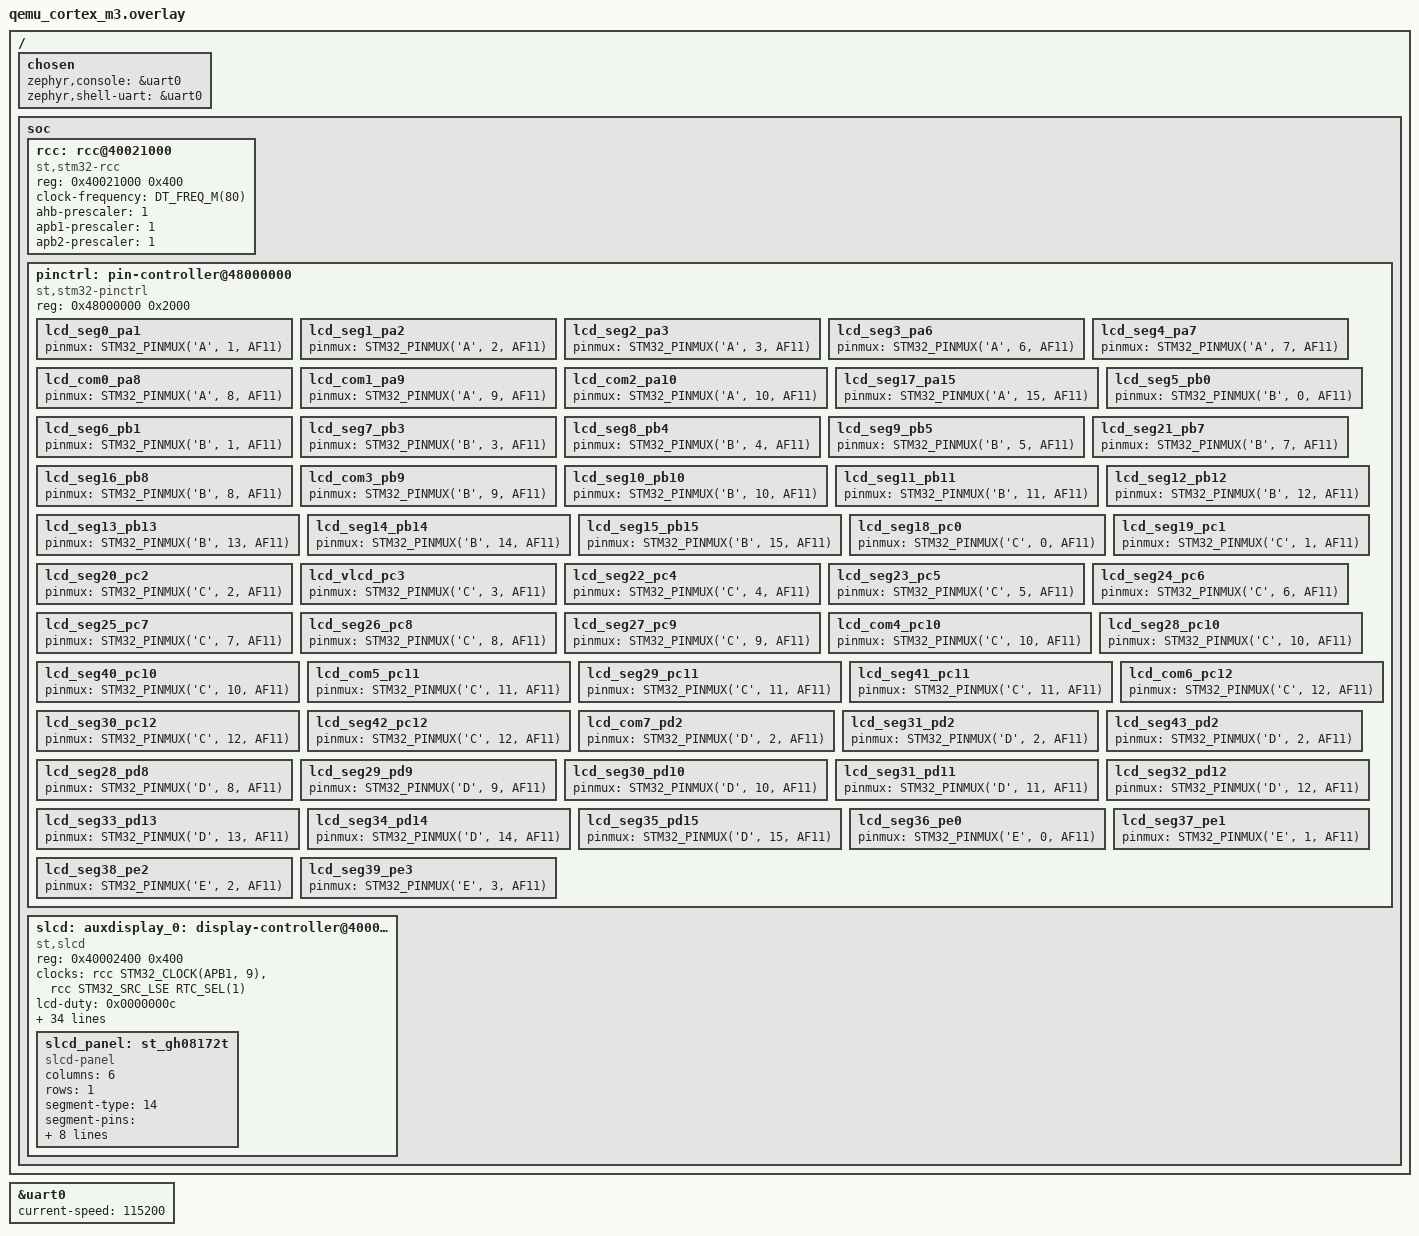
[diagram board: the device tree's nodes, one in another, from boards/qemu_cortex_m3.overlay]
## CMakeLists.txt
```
# SPDX-License-Identifier: Apache-2.0

message(STATUS "Start of CMakeList.txt")

cmake_minimum_required(VERSION 3.20.0)

message(STATUS "CMake current source dir is: ${CMAKE_CURRENT_SOURCE_DIR}")
list(APPEND DTS_ROOT "${CMAKE_CURRENT_SOURCE_DIR}")

find_package(Zephyr REQUIRED HINTS $ENV{ZEPHYR_BASE})

message(STATUS "Zephyr base is: ${ZEPHYR_BASE}")
list(APPEND DTS_ROOT "${ZEPHYR_BASE}/drivers/auxdisplay")

project(auxdisplay_14seg_qemu)

include_directories(SYSTEM src)
target_compile_options(app PRIVATE "-include" "${CMAKE_CURRENT_SOURCE_DIR}/src/mock_stm32l4xx_hal.h")
if(TARGET zephyr_interface)
	target_compile_options(zephyr_interface INTERFACE "-include" "${CMAKE_CURRENT_SOURCE_DIR}/src/mock_stm32l4xx_hal.h")
endif()

target_sources(app PRIVATE
	src/main.c
	src/mock_pinctrl_soc.c
	src/mock_stm32_clock_control.c
	src/mock_stm32l4xx_hal.c)

# Driver files to test
zephyr_library_include_directories("${CMAKE_CURRENT_SOURCE_DIR}/src")
zephyr_library_sources(
	"${ZEPHYR_BASE}/drivers/auxdisplay/auxdisplay_slcd_14seg.c"
	"${ZEPHYR_BASE}/drivers/auxdisplay/auxdisplay_st_slcd.c")

message(STATUS "End of CMakeList.txt")
```

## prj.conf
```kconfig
CONFIG_LOG=y
CONFIG_AUXDISPLAY=y

CONFIG_AUXDISPLAY_ST_SLCD=n

CONFIG_UART_CONSOLE=y

CONFIG_ZTEST=y
CONFIG_ZTEST_ASSERT_VERBOSE=3

# Added automatically by Workbench for Zephyr
#--- DEBUG PRESET - BEGIN ---#
# Set to -Og
CONFIG_DEBUG_OPTIMIZATIONS=y
# Thread awareness support
CONFIG_DEBUG_THREAD_INFO=y
# Generate stack usage per-function
CONFIG_STACK_USAGE=y
# Other options in case not set by default
CONFIG_BUILD_OUTPUT_HEX=y
CONFIG_BUILD_OUTPUT_META=y
CONFIG_OUTPUT_SYMBOLS=y
CONFIG_OUTPUT_STAT=y
CONFIG_OUTPUT_DISASSEMBLY=y
CONFIG_OUTPUT_PRINT_MEMORY_USAGE=y
#--- DEBUG PRESET - END ---#
```

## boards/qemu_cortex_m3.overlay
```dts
#include <zephyr/dt-bindings/clock/stm32l4_clock.h>
#include <freq.h>

/ {
	chosen {
		zephyr,console = &uart0;
		zephyr,shell-uart = &uart0;
	};

	soc {
		rcc: rcc@40021000 {
			compatible = "st,stm32-rcc";
			#clock-cells = <2>;
			reg = <0x40021000 0x400>;
		};

		pinctrl: pin-controller@48000000 {
			compatible = "st,stm32-pinctrl";
			reg = <0x48000000 0x2000>;
			#address-cells = <1>;
			#size-cells = <1>;
			reg = <0x48000000 0x2000>;
			ranges;
		};

		slcd: display-controller@40002400 {
			compatible = "st,slcd";
			reg = <0x40002400 0x400>;
			clocks = <&rcc STM32_CLOCK(APB1, 9)>, <&rcc STM32_SRC_LSE RTC_SEL(1)>;
			clock-names = "bus", "device";
		};
	};
};

&uart0 {
    status = "okay";
    current-speed = <115200>;
};

&rcc {
	//clocks = <&pll>;
	clock-frequency = <DT_FREQ_M(80)>;
	ahb-prescaler = <1>;
	apb1-prescaler = <1>;
	apb2-prescaler = <1>;
};

&slcd {
	status = "okay";
	lcd-duty = <0x0000000c>;
	lcd-bias = <0x00000040>;
	lcd-mux-segment = <0>;
	lcd-voltage-source = <0>;
	lcd-prescaler = <0>;
	lcd-divider = <0x003c0000>;
	lcd-contrast = <0x00001400>;
	lcd-pulse-on-duration = <0x00000040>;
	lcd-dead-time = <0>;
	lcd-high-drive = <0>;
	lcd-blink-mode = <0>;
	lcd-blink-frequency = <0x00004000>;
	pinctrl-0 = <&lcd_seg3_pa6 &lcd_seg4_pa7 &lcd_com0_pa8
		     &lcd_com1_pa9 &lcd_com2_pa10 &lcd_seg17_pa15
		     &lcd_seg5_pb0 &lcd_seg6_pb1 &lcd_seg8_pb4
		     &lcd_seg9_pb5 &lcd_com3_pb9 &lcd_seg12_pb12
		     &lcd_seg13_pb13 &lcd_seg14_pb14 &lcd_seg15_pb15
		     &lcd_vlcd_pc3 &lcd_seg22_pc4 &lcd_seg23_pc5
		     &lcd_seg24_pc6 &lcd_seg25_pc7 &lcd_seg26_pc8
		     &lcd_seg28_pd8 &lcd_seg29_pd9 &lcd_seg30_pd10 &lcd_seg31_pd11
		     &lcd_seg32_pd12 &lcd_seg33_pd13 &lcd_seg34_pd14 &lcd_seg35_pd15>;
	pinctrl-names = "default";
	pin-list = <4 23 6 13 15 29 31 33 35 25 17 8 9 26 24 34 32 30 28 14 12 5 22 3>;
	com-list = <0 2 4 6 1 3 5 7>;
	character-bit-list = <
			      /* MCU AFP11 channel for segment 1A-1P */
			      (1 << 22) (1 << 22) (1 << 23) (1 << 4) (1 << 4) (1 << 3) (1 << 3)
			      (1 << 3) (1 << 22) (1 << 22) (1 << 23) (1 << 4) (1 << 4) (1 << 3)
			      /* MCU AFP11 channel for segment 2A-2P */
			      (1 << 12) (1 << 12) (1 << 13) (1 << 6) (1 << 6) (1 << 5) (1 << 5)
			      (1 << 5) (1 << 12) (1 << 12) (1 << 13) (1 << 6) (1 << 6) (1 << 5)
			      /* MCU AFP11 channel for segment 1A-1P */
			      (1 << 28) (1 << 28) (1 << 29) (1 << 15) (1 << 15) (1 << 14) (1 << 14)
			      (1 << 14) (1 << 28) (1 << 28) (1 << 29) (1 << 15) (1 << 15) (1 << 14)
			      /* MCU AFP11 channel for segment 2A-2P */
			      (1 << 0) (1 << 0) (1 << 1) (1 << 31) (1 << 31) (1 << 30) (1 << 30)
			      (1 << 30) (1 << 0) (1 << 0) (1 << 1) (1 << 31) (1 << 31) (1 << 30)
			      /* MCU AFP11 channel for segment 3A-3P */
			      (1 << 24) (1 << 24) (1 << 25) (1 << 3) (1 << 3) (1 << 2) (1 << 2)
			      (1 << 2)
			      (1 << 24) (1 << 24) (1 << 25) (1 << 3) (1 << 3) (1 << 2)
			      /* MCU AFP11 channel for segment 4A-4P */
			      (1 << 9) (1 << 9) (1 << 8) (1 << 17) (1 << 17) (1 << 26) (1 << 26)
			      (1 << 26)
			      (1 << 9) (1 << 9) (1 << 8) (1 << 17) (1 << 17) (1 << 26)>;
	character-com-list = <
			      /* COM RAM register for segment 1A-1P */
			      2 0 2 2 0 2 0 6 6 4 0 6 4 4
			      /* COM RAM register for segment 2A-2P */
			      2 0 2 2 0 2 0 6 6 4 0 6 4 4
			      /* COM RAM register for segment 1A-1P */
			      2 0 2 2 0 2 0 6 6 4 0 6 4 4
			      /* COM RAM register for segment 2A-2P */
			      3 1 3 2 0 2 0 6 7 5 1 6 4 4
			      /* COM RAM register for segment 3A-3P */
			      2 0 2 3 1 3 1 7 6 4 0 7 5 5
			      /* COM RAM register for segment 4A-4P */
			      2 0 2 2 0 2 0 6 6 4 0 6 4 4>;
	indicator-bit-list = <(1 << 23) (1 << 23) (1 << 13) (1 << 13)
			      (1 << 29) (1 << 29) (1 << 1) (1 << 1)
			      (1 << 8) (1 << 8) (1 << 25) (1 << 25)>;
	indicator-com-list = <6 4 6 4 6 4 7 5 6 4 6 4>;
	custom-character-slot-count = <32>;
};

auxdisplay_0: &slcd {
	slcd_panel: st_gh08172t {
		compatible = "slcd-panel";
		columns = <6>;
		rows = <1>;
		segment-type = <14>; /* 14 segment SLCD panel */
		/* Which pin controls which segment. 6 positions x 14 segments = 84 elements.
		 * Segment order per position: A B C D E F G H J K M N O P
		 * Since the display starts from left to right
		 */
		segment-pins = <
				/* Pins for dig1 segments(1A~1P) */
				22 22 1 0 0 23 23 23 22 22 1 0 0 23
				/* Pins for dig2 segments(2A~2P) */
				20 20 3 2 2 21 21 21 20 20 3 2 2 21
				/* Pins for dig3 segments(3A~3P) */
				18 18 5 4 4 19 19 19 18 18 5 4 4 19
				/* Pins for dig4 segments(4A~4P) */
				16 16 7 6 6 17 17 17 16 16 7 6 6 17
				/* Pins for dig5 segments(5A~5P) */
				14 14 9 8 8 15 15 15 14 14 9 8 8 15
				/* Pins for dig6 segments(6A~6P) */
				12 12 11 10 10 13 13 13 12 12 11 10 10 13>;

		/* Which com controls which segment. 6 positions x 14 segments = 84 elements. */
		segment-coms = <
				/* COMs for dig1 segments(1A~1P) */
				1 0 1 1 0 1 0 3 3 2 0 3 2 2
				/* COMs for dig2 segments(2A~2P) */
				1 0 1 1 0 1 0 3 3 2 0 3 2 2
				/* COMs for dig3 segments(3A~3P) */
				1 0 1 1 0 1 0 3 3 2 0 3 2 2
				/* COMs for dig4 segments(4A~4P) */
				1 0 1 1 0 1 0 3 3 2 0 3 2 2
				/* COMs for dig5 segments(5A~5P) */
				1 0 1 1 0 1 0 3 3 2 0 3 2 2
				/* COMs for dig6 segments(6A~6P) */
				1 0 1 1 0 1 0 3 3 2 0 3 2 2>;

		num-indicators = <12>;
		indicator-pins = <1 1 3 3 5 5 7 7 11 11 9 9>;
		indicator-coms = <3 2 3 2 3 2 3 2 3 2 3 2>;
		display-indicators = <
				      /* Single dot */
				      0 2 4 6 0xff 0xff
				      /* Double dot (colon) */
				      1 3 5 7 0xff 0xff
				      /* 4 bars, BAR0-BAR3 */
				      0xff 0xff 0xff 0xff 0xff 8
				      0xff 0xff 0xff 0xff 0xff 9
				      0xff 0xff 0xff 0xff 0xff 10
				      0xff 0xff 0xff 0xff 0xff 11>;
	};
};

#include <zephyr/dt-bindings/pinctrl/stm32-pinctrl.h>

&pinctrl {
	/* LCD */

	/omit-if-no-ref/ lcd_seg0_pa1: lcd_seg0_pa1 {
		pinmux = <STM32_PINMUX('A', 1, AF11)>;
	};

	/omit-if-no-ref/ lcd_seg1_pa2: lcd_seg1_pa2 {
		pinmux = <STM32_PINMUX('A', 2, AF11)>;
	};

	/omit-if-no-ref/ lcd_seg2_pa3: lcd_seg2_pa3 {
		pinmux = <STM32_PINMUX('A', 3, AF11)>;
	};

	/omit-if-no-ref/ lcd_seg3_pa6: lcd_seg3_pa6 {
		pinmux = <STM32_PINMUX('A', 6, AF11)>;
	};

	/omit-if-no-ref/ lcd_seg4_pa7: lcd_seg4_pa7 {
		pinmux = <STM32_PINMUX('A', 7, AF11)>;
	};

	/omit-if-no-ref/ lcd_com0_pa8: lcd_com0_pa8 {
		pinmux = <STM32_PINMUX('A', 8, AF11)>;
	};

	/omit-if-no-ref/ lcd_com1_pa9: lcd_com1_pa9 {
		pinmux = <STM32_PINMUX('A', 9, AF11)>;
	};

	/omit-if-no-ref/ lcd_com2_pa10: lcd_com2_pa10 {
		pinmux = <STM32_PINMUX('A', 10, AF11)>;
	};

	/omit-if-no-ref/ lcd_seg17_pa15: lcd_seg17_pa15 {
		pinmux = <STM32_PINMUX('A', 15, AF11)>;
	};

	/omit-if-no-ref/ lcd_seg5_pb0: lcd_seg5_pb0 {
		pinmux = <STM32_PINMUX('B', 0, AF11)>;
	};

	/omit-if-no-ref/ lcd_seg6_pb1: lcd_seg6_pb1 {
		pinmux = <STM32_PINMUX('B', 1, AF11)>;
	};

	/omit-if-no-ref/ lcd_seg7_pb3: lcd_seg7_pb3 {
		pinmux = <STM32_PINMUX('B', 3, AF11)>;
	};

	/omit-if-no-ref/ lcd_seg8_pb4: lcd_seg8_pb4 {
		pinmux = <STM32_PINMUX('B', 4, AF11)>;
	};

	/omit-if-no-ref/ lcd_seg9_pb5: lcd_seg9_pb5 {
		pinmux = <STM32_PINMUX('B', 5, AF11)>;
	};

	/omit-if-no-ref/ lcd_seg21_pb7: lcd_seg21_pb7 {
		pinmux = <STM32_PINMUX('B', 7, AF11)>;
	};

	/omit-if-no-ref/ lcd_seg16_pb8: lcd_seg16_pb8 {
		pinmux = <STM32_PINMUX('B', 8, AF11)>;
	};

	/omit-if-no-ref/ lcd_com3_pb9: lcd_com3_pb9 {
		pinmux = <STM32_PINMUX('B', 9, AF11)>;
	};

	/omit-if-no-ref/ lcd_seg10_pb10: lcd_seg10_pb10 {
		pinmux = <STM32_PINMUX('B', 10, AF11)>;
	};

	/omit-if-no-ref/ lcd_seg11_pb11: lcd_seg11_pb11 {
		pinmux = <STM32_PINMUX('B', 11, AF11)>;
	};

	/omit-if-no-ref/ lcd_seg12_pb12: lcd_seg12_pb12 {
		pinmux = <STM32_PINMUX('B', 12, AF11)>;
	};

	/omit-if-no-ref/ lcd_seg13_pb13: lcd_seg13_pb13 {
		pinmux = <STM32_PINMUX('B', 13, AF11)>;
	};

	/omit-if-no-ref/ lcd_seg14_pb14: lcd_seg14_pb14 {
		pinmux = <STM32_PINMUX('B', 14, AF11)>;
	};

	/omit-if-no-ref/ lcd_seg15_pb15: lcd_seg15_pb15 {
		pinmux = <STM32_PINMUX('B', 15, AF11)>;
	};

	/omit-if-no-ref/ lcd_seg18_pc0: lcd_seg18_pc0 {
		pinmux = <STM32_PINMUX('C', 0, AF11)>;
	};

	/omit-if-no-ref/ lcd_seg19_pc1: lcd_seg19_pc1 {
		pinmux = <STM32_PINMUX('C', 1, AF11)>;
	};

	/omit-if-no-ref/ lcd_seg20_pc2: lcd_seg20_pc2 {
		pinmux = <STM32_PINMUX('C', 2, AF11)>;
	};

	/omit-if-no-ref/ lcd_vlcd_pc3: lcd_vlcd_pc3 {
		pinmux = <STM32_PINMUX('C', 3, AF11)>;
	};

	/omit-if-no-ref/ lcd_seg22_pc4: lcd_seg22_pc4 {
		pinmux = <STM32_PINMUX('C', 4, AF11)>;
	};

	/omit-if-no-ref/ lcd_seg23_pc5: lcd_seg23_pc5 {
		pinmux = <STM32_PINMUX('C', 5, AF11)>;
	};

	/omit-if-no-ref/ lcd_seg24_pc6: lcd_seg24_pc6 {
		pinmux = <STM32_PINMUX('C', 6, AF11)>;
	};

	/omit-if-no-ref/ lcd_seg25_pc7: lcd_seg25_pc7 {
		pinmux = <STM32_PINMUX('C', 7, AF11)>;
	};

	/omit-if-no-ref/ lcd_seg26_pc8: lcd_seg26_pc8 {
		pinmux = <STM32_PINMUX('C', 8, AF11)>;
	};

	/omit-if-no-ref/ lcd_seg27_pc9: lcd_seg27_pc9 {
		pinmux = <STM32_PINMUX('C', 9, AF11)>;
	};

	/omit-if-no-ref/ lcd_com4_pc10: lcd_com4_pc10 {
		pinmux = <STM32_PINMUX('C', 10, AF11)>;
	};

	/omit-if-no-ref/ lcd_seg28_pc10: lcd_seg28_pc10 {
		pinmux = <STM32_PINMUX('C', 10, AF11)>;
	};

	/omit-if-no-ref/ lcd_seg40_pc10: lcd_seg40_pc10 {
		pinmux = <STM32_PINMUX('C', 10, AF11)>;
	};

	/omit-if-no-ref/ lcd_com5_pc11: lcd_com5_pc11 {
		pinmux = <STM32_PINMUX('C', 11, AF11)>;
	};

	/omit-if-no-ref/ lcd_seg29_pc11: lcd_seg29_pc11 {
		pinmux = <STM32_PINMUX('C', 11, AF11)>;
	};

	/omit-if-no-ref/ lcd_seg41_pc11: lcd_seg41_pc11 {
		pinmux = <STM32_PINMUX('C', 11, AF11)>;
	};

	/omit-if-no-ref/ lcd_com6_pc12: lcd_com6_pc12 {
		pinmux = <STM32_PINMUX('C', 12, AF11)>;
	};

	/omit-if-no-ref/ lcd_seg30_pc12: lcd_seg30_pc12 {
		pinmux = <STM32_PINMUX('C', 12, AF11)>;
	};

	/omit-if-no-ref/ lcd_seg42_pc12: lcd_seg42_pc12 {
		pinmux = <STM32_PINMUX('C', 12, AF11)>;
	};

	/omit-if-no-ref/ lcd_com7_pd2: lcd_com7_pd2 {
		pinmux = <STM32_PINMUX('D', 2, AF11)>;
	};

	/omit-if-no-ref/ lcd_seg31_pd2: lcd_seg31_pd2 {
		pinmux = <STM32_PINMUX('D', 2, AF11)>;
	};

	/omit-if-no-ref/ lcd_seg43_pd2: lcd_seg43_pd2 {
		pinmux = <STM32_PINMUX('D', 2, AF11)>;
	};

	/omit-if-no-ref/ lcd_seg28_pd8: lcd_seg28_pd8 {
		pinmux = <STM32_PINMUX('D', 8, AF11)>;
	};

	/omit-if-no-ref/ lcd_seg29_pd9: lcd_seg29_pd9 {
		pinmux = <STM32_PINMUX('D', 9, AF11)>;
	};

	/omit-if-no-ref/ lcd_seg30_pd10: lcd_seg30_pd10 {
		pinmux = <STM32_PINMUX('D', 10, AF11)>;
	};

	/omit-if-no-ref/ lcd_seg31_pd11: lcd_seg31_pd11 {
		pinmux = <STM32_PINMUX('D', 11, AF11)>;
	};

	/omit-if-no-ref/ lcd_seg32_pd12: lcd_seg32_pd12 {
		pinmux = <STM32_PINMUX('D', 12, AF11)>;
	};

	/omit-if-no-ref/ lcd_seg33_pd13: lcd_seg33_pd13 {
		pinmux = <STM32_PINMUX('D', 13, AF11)>;
	};

	/omit-if-no-ref/ lcd_seg34_pd14: lcd_seg34_pd14 {
		pinmux = <STM32_PINMUX('D', 14, AF11)>;
	};

	/omit-if-no-ref/ lcd_seg35_pd15: lcd_seg35_pd15 {
		pinmux = <STM32_PINMUX('D', 15, AF11)>;
	};

	/omit-if-no-ref/ lcd_seg36_pe0: lcd_seg36_pe0 {
		pinmux = <STM32_PINMUX('E', 0, AF11)>;
	};

	/omit-if-no-ref/ lcd_seg37_pe1: lcd_seg37_pe1 {
		pinmux = <STM32_PINMUX('E', 1, AF11)>;
	};

	/omit-if-no-ref/ lcd_seg38_pe2: lcd_seg38_pe2 {
		pinmux = <STM32_PINMUX('E', 2, AF11)>;
	};

	/omit-if-no-ref/ lcd_seg39_pe3: lcd_seg39_pe3 {
		pinmux = <STM32_PINMUX('E', 3, AF11)>;
	};
};
```

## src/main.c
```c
/*
 * Copyright (c) 2026 Renato Mauro
 *
 * SPDX-License-Identifier: Apache-2.0
 */

#include <string.h>
#include <zephyr/kernel.h>
#include <zephyr/device.h>
#include <zephyr/drivers/auxdisplay.h>
#include <zephyr/logging/log.h>
#include <zephyr/ztest.h>

LOG_MODULE_REGISTER(auxdisplay_14seg_qemu, LOG_LEVEL_DBG);

struct auxdisplay_panel_config {
	struct auxdisplay_capabilities capabilities;
	const bool rotated;
	const uint8_t segment_type;
	const uint16_t *digits; /* Digits coding array. */
	const uint16_t *digits_rotated_180;
	const uint16_t *letters_upper; /* Upper Letter coding array. */
	const uint16_t *letters_upper_rotated_180;
	const uint16_t *letters_lower; /* Lower Letter coding array. */
	const uint16_t *letters_lower_rotated_180;
	/*
	 * Pin/com configurations of the segments/indicators read from the
	 * panel overlay configuration.
	 */
	const uint8_t *segment_pins;
	const uint8_t *segment_coms;
	const uint8_t num_indicators;
	const uint8_t *indicator_pins;       /* Optional. NULL if DT property absent */
	const uint8_t *indicator_coms;       /* Optional. NULL if DT property absent */
	const uint8_t *display_indicators;   /* Optional. NULL if DT property absent */
	const uint8_t *col_indicators;       /* Optional. NULL if DT property absent */
	const uint8_t *upper_dot_indicators; /* Optional. NULL if DT property absent */
	const uint8_t *lower_dot_indicators; /* Optional. NULL if DT property absent */
};

struct auxdisplay_st_slcd_config {
	const struct stm32_pclken *pclken;
	const struct device *clk_dev;
	const struct pinctrl_dev_config *pincfg;

	const uint8_t *pin_list;
	const uint8_t pin_list_len;
	const uint8_t com_list_len;
	const uint8_t ram_buffer_size;

	const uint8_t custom_character_slot_count;
	const uint32_t *character_bit_list;
	const uint8_t *character_com_list;
	const uint32_t *indicator_bit_list;
	const uint8_t *indicator_com_list;

	const struct auxdisplay_panel_config *panel_config;
	const int position_count;
};

extern uint16_t
slcd_14seg_convert_ascii_char_to_14seg_pattern(const struct auxdisplay_panel_config *panel,
					       uint8_t ascii_char);

struct full_test_fixture {
	const struct device *display;
	const struct auxdisplay_panel_config *panel_config;
};

static void *suite_setup(void)
{
	static struct full_test_fixture context;

	context.display = DEVICE_DT_GET(DT_NODELABEL(auxdisplay_0));
	context.panel_config = ((const struct auxdisplay_st_slcd_config *)context.display->config)->panel_config;
	return &context;
}

ZTEST_SUITE(full_test, NULL, suite_setup, NULL, NULL, NULL);

ZTEST_F(full_test, test_display_ready)
{
	zassert_not_null(fixture->display, "Segment LCD device not instantiated");
	zassert_true(device_is_ready(fixture->display),
		     "Segment LCD device is not ready for operation");
	zassert_not_null(fixture->panel_config, "Segment LCD panel config not found");
}

ZTEST_F(full_test, test_auxdisplay_write_uppercase_a)
{
	const char t = 'A';
	int rc = auxdisplay_write(fixture->display, (const uint8_t *)&t, 1);
	zassert_equal(rc, 0, "La scrittura su auxdisplay ha fallito (%d)", rc);
}

ZTEST_F(full_test, test_auxdisplay_write_uppercase_z)
{
	const char t = 'Z';
	int rc = auxdisplay_write(fixture->display, (const uint8_t *)&t, 1);

	zassert_equal(rc, 0, "La scrittura su auxdisplay ha fallito (%d)", rc);
}

ZTEST_F(full_test, test_slcd_14seg_convert_ascii_char_to_14seg_pattern_uppercase_a)
{
	uint16_t pattern = slcd_14seg_convert_ascii_char_to_14seg_pattern(fixture->panel_config, 'A');

	zassert_equal(pattern, 0x477, "Pattern for letter 'A' is wrong (0x%x)", pattern);
}

ZTEST_F(full_test, test_slcd_14seg_convert_ascii_char_to_14seg_pattern_uppercase_z)
{
	uint16_t pattern = slcd_14seg_convert_ascii_char_to_14seg_pattern(fixture->panel_config, 'Z');

	zassert_equal(pattern, 0x2209, "Pattern for letter 'A' is wrong (0x%x)", pattern);
}
```

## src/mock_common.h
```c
/*
 * Copyright 2026 Renato Mauro
 *
 * SPDX-License-Identifier: Apache-2.0
 */

#ifndef MOCK_COMMON_H
#define MOCK_COMMON_H

#include <stdint.h>

#ifdef __used
#undef __used
#endif

/* Define mock identifiers and types to make the code compile */
#if !defined(UNUSED)
#define UNUSED(x) ((void)(x))
#endif

#endif /* MOCK_COMMON_H */
```

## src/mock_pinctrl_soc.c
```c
/*
 * Copyright (c) 2026 Renato Mauro
 *
 * SPDX-License-Identifier: Apache-2.0
 */

#include <string.h>
#include <zephyr/kernel.h>
#include <zephyr/device.h>

#include "mock_common.h"
/** pinctrl_soc.h is included via pinctrl.h, that exists also in the QEMU environment.
 * For this reason, it must be mocked with a file having the same name.
 */
#include "pinctrl_soc.h"

struct pinctrl_dev_config;

int pinctrl_lookup_state(const struct pinctrl_dev_config *config, uint8_t state, uint8_t *idx)
{
	UNUSED(config);
	UNUSED(state);
	if (idx) {
		*idx = 0;
	}
	return 0;
}

int pinctrl_configure_pins(const pinctrl_soc_pin_t *pins, uint8_t pin_cnt, uintptr_t reg)
{
	UNUSED(pins);
	UNUSED(pin_cnt);
	UNUSED(reg);
	return 0;
}
```

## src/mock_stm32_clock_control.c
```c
/*
 * Copyright (c) 2026 Renato Mauro
 *
 * SPDX-License-Identifier: Apache-2.0
 */

#include <string.h>
#include <zephyr/kernel.h>
#include <zephyr/device.h>

#include <zephyr/toolchain.h>
#include <zephyr/drivers/clock_control.h>

#include "mock_common.h"
#include "mock_stm32_clock_control.h"

static struct device_state mock_device_state = {
	.init_res = 0, /* 0 in Zephyr means successfully initialized */
	.initialized = true,
};

static int mock_clock_on(const struct device *dev, clock_control_subsys_t sys)
{
	UNUSED(dev);
	UNUSED(sys);
	return 0; /* Ritorna successo */
}

static int mock_clock_off(const struct device *dev, clock_control_subsys_t sys)
{
	UNUSED(dev);
	UNUSED(sys);
	return 0;
}

/* The clock api mock struct must be positioned in the right section. */
STRUCT_SECTION_ITERABLE(clock_control_driver_api, mock_clock_api) = {
	.on = mock_clock_on,
	.off = mock_clock_off,
};

/* Resolution of __device_dts_ord_20:
 * The driver searches for a 'struct device' generated by DeviceTree.
 * Create a static mock in RAM named as requested by the linker.
 */
const struct device __device_dts_ord_20 = {
	.name = "mock_stm32_clock_control",
	.api = &mock_clock_api,
	.state = &mock_device_state,
};
```

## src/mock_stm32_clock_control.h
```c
/*
 * Copyright 2026 Renato Mauro
 *
 * SPDX-License-Identifier: Apache-2.0
 */

#ifndef MOCK_STM32_CLOCK_CONTROL_H
#define MOCK_STM32_CLOCK_CONTROL_H

#define STM32_CLOCK_DIV_SHIFT 12

struct stm32_pclken {
	uint32_t bus: STM32_CLOCK_DIV_SHIFT;
	uint32_t div: (32 - STM32_CLOCK_DIV_SHIFT);
	uint32_t enr;
};

#endif /* MOCK_STM32_CLOCK_CONTROL_H */
```

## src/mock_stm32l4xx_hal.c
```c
/*
 * Copyright (c) 2026 Renato Mauro
 *
 * SPDX-License-Identifier: Apache-2.0
 */

#include <string.h>
#include <zephyr/kernel.h>
#include <zephyr/device.h>

#include "mock_stm32l4xx_hal.h"

HAL_StatusTypeDef HAL_LCD_Clear(LCD_HandleTypeDef *hlcd)
{
	UNUSED(hlcd);
	/* No operation in QEMU */
	return HAL_OK;
}

HAL_StatusTypeDef HAL_LCD_Write(LCD_HandleTypeDef *hlcd, uint32_t RAMRegisterIndex,
				uint32_t RAMRegisterMask, uint32_t Data)
{
	UNUSED(hlcd);
	UNUSED(RAMRegisterIndex);
	UNUSED(RAMRegisterMask);
	UNUSED(Data);
	/* No operation in QEMU */
	return HAL_OK;
}

HAL_StatusTypeDef HAL_LCD_UpdateDisplayRequest(LCD_HandleTypeDef *hlcd)
{
	UNUSED(hlcd);
	/* No operation in QEMU */
	return HAL_OK;
}

HAL_StatusTypeDef HAL_LCD_Init(LCD_HandleTypeDef *hlcd)
{
	/* No operation in QEMU */
	return HAL_OK;
}
```

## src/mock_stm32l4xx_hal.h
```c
/*
 * Copyright 2026 Renato Mauro
 *
 * SPDX-License-Identifier: Apache-2.0
 */

#ifndef MOCK_STM32L4XX_HAL_H
#define MOCK_STM32L4XX_HAL_H

/** This header is included by some other Zephyr sources, so stdint.h must be included here, not
 * only in the C file. And everything must be hidden to the assembly compiler.
 */
#ifndef __ASSEMBLER__

#include "mock_common.h"

typedef struct {
	int n;
} LCD_TypeDef;

typedef struct {
	uint32_t Prescaler;     /*!< Configures the LCD Prescaler.
				     This parameter can be one value of @ref LCD_Prescaler */
	uint32_t Divider;       /*!< Configures the LCD Divider.
				     This parameter can be one value of @ref LCD_Divider */
	uint32_t Duty;          /*!< Configures the LCD Duty.
				     This parameter can be one value of @ref LCD_Duty */
	uint32_t Bias;          /*!< Configures the LCD Bias.
				     This parameter can be one value of @ref LCD_Bias */
	uint32_t VoltageSource; /*!< Selects the LCD Voltage source.
				     This parameter can be one value of @ref LCD_Voltage_Source */
	uint32_t Contrast;      /*!< Configures the LCD Contrast.
				     This parameter can be one value of @ref LCD_Contrast */
	uint32_t DeadTime;      /*!< Configures the LCD Dead Time.
				     This parameter can be one value of @ref LCD_DeadTime */
	uint32_t
		PulseOnDuration; /*!< Configures the LCD Pulse On Duration.
				      This parameter can be one value of @ref LCD_PulseOnDuration */
	uint32_t HighDrive;      /*!< Configures the LCD High Drive.
				       This parameter can be one value of @ref LCD_HighDrive */
	uint32_t BlinkMode;      /*!< Configures the LCD Blink Mode.
				      This parameter can be one value of @ref LCD_BlinkMode */
	uint32_t BlinkFrequency; /*!< Configures the LCD Blink frequency.
				      This parameter can be one value of @ref LCD_BlinkFrequency */
	uint32_t MuxSegment;     /*!< Enable or disable mux segment.
				      This parameter can be one value of @ref LCD_MuxSegment */
} LCD_InitTypeDef;

typedef struct {
	LCD_TypeDef *Instance; /* LCD registers base address */

	LCD_InitTypeDef Init; /* LCD communication parameters */

} LCD_HandleTypeDef;

typedef enum {
	HAL_OK = 0x00,
	HAL_ERROR = 0x01,
	HAL_BUSY = 0x02,
	HAL_TIMEOUT = 0x03
} HAL_StatusTypeDef;

#define __HAL_LCD_ENABLE(__HANDLE__)  UNUSED(__HANDLE__)
#define __HAL_LCD_DISABLE(__HANDLE__) UNUSED(__HANDLE__)

HAL_StatusTypeDef HAL_LCD_Clear(LCD_HandleTypeDef *hlcd);
HAL_StatusTypeDef HAL_LCD_Write(LCD_HandleTypeDef *hlcd, uint32_t RAMRegisterIndex,
				uint32_t RAMRegisterMask, uint32_t Data);
HAL_StatusTypeDef HAL_LCD_UpdateDisplayRequest(LCD_HandleTypeDef *hlcd);
HAL_StatusTypeDef HAL_LCD_Init(LCD_HandleTypeDef *hlcd);

#endif /* __ASSEMBLER__ */

#endif /* MOCK_STM32L4XX_HAL_H */
```

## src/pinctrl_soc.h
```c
/*
 * Copyright 2026 Renato Mauro
 *
 * SPDX-License-Identifier: Apache-2.0
 */

#ifndef MOCK_PINCTRL_SOC_H
#define MOCK_PINCTRL_SOC_H

typedef uint32_t pinctrl_soc_pin_t;

#define Z_PINCTRL_STATE_PINS_INIT(node_id, prop) {0}

#endif /* MOCK_PINCTRL_SOC_H */
```
